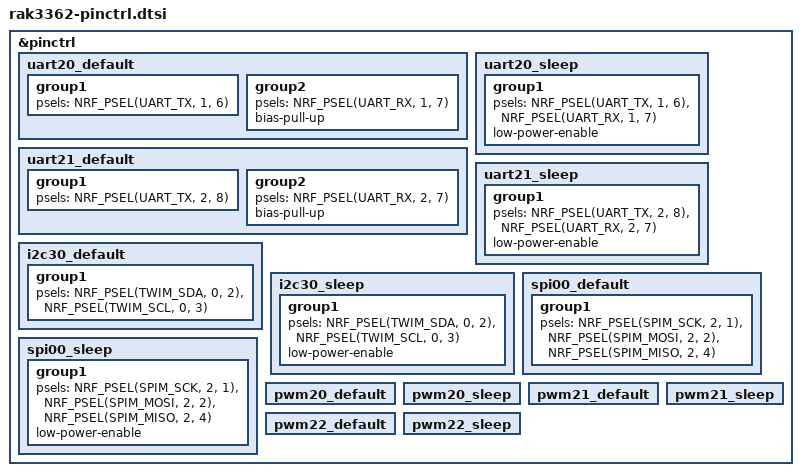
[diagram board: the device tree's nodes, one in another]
/*
 * Copyright (c) 2026 RAKwireless Technology Limited
 * SPDX-License-Identifier: Apache-2.0
 */

#include <zephyr/dt-bindings/pinctrl/nrf-pinctrl.h>

&pinctrl {
	uart20_default: uart20_default {
		group1 {
			psels = <NRF_PSEL(UART_TX, 1, 6)>;
		};
		group2 {
			psels = <NRF_PSEL(UART_RX, 1, 7)>;
			bias-pull-up;
		};
	};

	uart20_sleep: uart20_sleep {
		group1 {
			psels = <NRF_PSEL(UART_TX, 1, 6)>,
				<NRF_PSEL(UART_RX, 1, 7)>;
			low-power-enable;
		};
	};

	uart21_default: uart21_default {
		group1 {
			psels = <NRF_PSEL(UART_TX, 2, 8)>;
		};
		group2 {
			psels = <NRF_PSEL(UART_RX, 2, 7)>;
			bias-pull-up;
		};
	};

	uart21_sleep: uart21_sleep {
		group1 {
			psels = <NRF_PSEL(UART_TX, 2, 8)>,
				<NRF_PSEL(UART_RX, 2, 7)>;
			low-power-enable;
		};
	};

	i2c30_default: i2c30_default {
		group1 {
			psels = <NRF_PSEL(TWIM_SDA, 0, 2)>,
				<NRF_PSEL(TWIM_SCL, 0, 3)>;
		};
	};

	i2c30_sleep: i2c30_sleep {
		group1 {
			psels = <NRF_PSEL(TWIM_SDA, 0, 2)>,
				<NRF_PSEL(TWIM_SCL, 0, 3)>;
			low-power-enable;
		};
	};

	spi00_default: spi00_default {
		group1 {
			psels = <NRF_PSEL(SPIM_SCK,  2, 1)>,
				<NRF_PSEL(SPIM_MOSI, 2, 2)>,
				<NRF_PSEL(SPIM_MISO, 2, 4)>;
		};
	};

	spi00_sleep: spi00_sleep {
		group1 {
			psels = <NRF_PSEL(SPIM_SCK,  2, 1)>,
				<NRF_PSEL(SPIM_MOSI, 2, 2)>,
				<NRF_PSEL(SPIM_MISO, 2, 4)>;
			low-power-enable;
		};
	};

	/*
	 * PWM pinctrl states are intentionally empty. board.c computes pin
	 * assignments at compile time from installed shield DT nodes and
	 * installs them via pinctrl_update_states() at boot, before the
	 * PWM driver applies pinctrl at POST_KERNEL.
	 */
	pwm20_default: pwm20_default {
	};

	pwm20_sleep: pwm20_sleep {
	};

	pwm21_default: pwm21_default {
	};

	pwm21_sleep: pwm21_sleep {
	};

	pwm22_default: pwm22_default {
	};

	pwm22_sleep: pwm22_sleep {
	};
};
